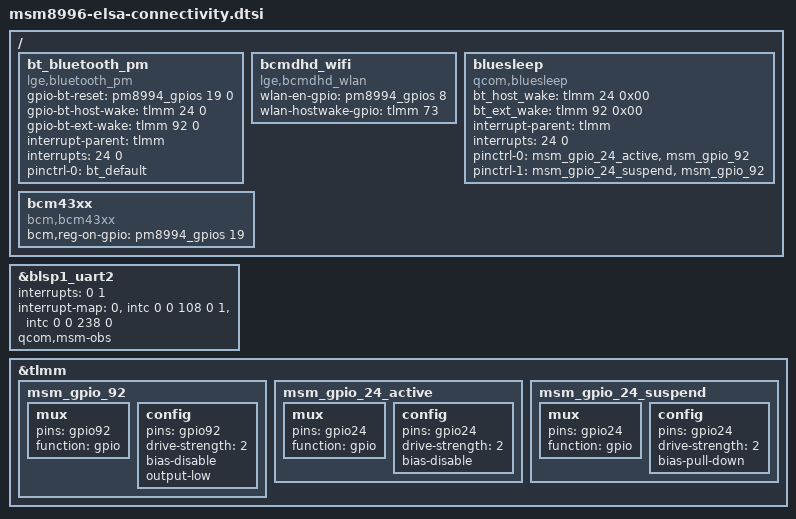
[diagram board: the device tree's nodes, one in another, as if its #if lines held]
/* Copyright (c) 2015, The Linux Foundation. All rights reserved.
 * Copyright (c) 2017, The LineageOS Project. All rights reserved.
 *
 * This program is free software; you can redistribute it and/or modify
 * it under the terms of the GNU General Public License version 2 and
 * only version 2 as published by the Free Software Foundation.
 *
 * This program is distributed in the hope that it will be useful,
 * but WITHOUT ANY WARRANTY; without even the implied warranty of
 * MERCHANTABILITY or FITNESS FOR A PARTICULAR PURPOSE.  See the
 * GNU General Public License for more details.
 */


#if (defined(CONFIG_LINE_DISCIPLINE_DRIVER) || defined(CONFIG_LINE_DISCIPLINE_DRIVER_MODULE)) && (defined(CONFIG_BT_BCM43XX) || defined(CONFIG_BT_BCM43XX_MODULE))
#error "CONFIG_LINE_DISCIPLINE_DRIVER and CONFIG_BT_BCM43XX conflict, cannot continue!"
#elif !defined(CONFIG_LINE_DISCIPLINE_DRIVER) && !defined(CONFIG_LINE_DISCIPLINE_DRIVER_MODULE) && !defined(CONFIG_BT_BCM43XX) && !defined(CONFIG_BT_BCM43XX_MODULE)
#warning "No Bluetooth implementation selected, are you aure about that?"
#endif


#if defined(CONFIG_LINE_DISCIPLINE_DRIVER) || defined(CONFIG_LINE_DISCIPLINE_DRIVER_MODULE)
/*[H1_BT_BRINGUP_S]*/
&blsp1_uart2 {
	interrupt-names = "core_irq", "bam_irq";
	interrupts = <0 1>;
	interrupt-map = <0 &intc 0 0 108 0
			1 &intc 0 0 238 0>;
	/delete-property/ qcom,inject-rx-on-wakeup;
	/delete-property/ qcom,rx-char-to-inject;
	qcom,msm-obs;
};
/*[H1_BT_BRINGUP_E]*/
#endif

/ {
#if defined(CONFIG_LINE_DISCIPLINE_DRIVER) || defined(CONFIG_LINE_DISCIPLINE_DRIVER_MODULE)
	/*[H1_BT_BRINGUP_S]*/
	bt_bluetooth_pm {
		compatible = "lge,bluetooth_pm";
		gpio-bt-reset = <&pm8994_gpios 19 0>;
		gpio-bt-host-wake = <&tlmm 24 0>;
		gpio-bt-ext-wake = <&tlmm 92 0>;
		interrupt-parent = <&tlmm>;
		interrupts = <24 0>;
		interrupt-names = "host_wake_interrupt";

		pinctrl-names = "bt_default";
		pinctrl-0 = <&bt_default>;
	};
	/*[H1_BT_BRINGUP_E]*/
#endif

	/* BCMDHD for Wi-Fi */
	bcmdhd_wifi {
		compatible = "lge,bcmdhd_wlan";
		wlan-en-gpio = <&pm8994_gpios 8 0>;
		wlan-hostwake-gpio = <&tlmm 73 0>;
	};

#if defined(CONFIG_BT_BCM43XX) || defined(CONFIG_BT_BCM43XX_MODULE)
	bluesleep {
		compatible = "qcom,bluesleep";
		bt_host_wake = <&tlmm 24 0x00>; /* BT_HOST_WAKE */
		bt_ext_wake = <&tlmm 92 0x00>; /* BT_DEV_WAKE */
		interrupt-parent = <&tlmm>;
		interrupts = <24 0>;
		interrupt-names = "host_wake";
		pinctrl-names = "default", "sleep";
		pinctrl-0 = <&msm_gpio_24_active &msm_gpio_92>;
		pinctrl-1 = <&msm_gpio_24_suspend &msm_gpio_92>;
	};

	bcm43xx {
		compatible = "bcm,bcm43xx";
		bcm,reg-on-gpio = <&pm8994_gpios 19 0x00>; /* BT_REG_ON */
	};
};

&tlmm {
	/* GPIO_92 : BT_DEV_WAKE */
	msm_gpio_92: msm_gpio_92 {
		mux {
			pins = "gpio92";
			function = "gpio";
		};

		config {
			pins = "gpio92";
			drive-strength = <2>;
			bias-disable;
			output-low;
		};
	};

	/* GPIO_24 : BT_HOST_WAKE */
	msm_gpio_24_active: msm_gpio_24_active {
		mux {
			pins = "gpio24";
			function = "gpio";
		};

		config {
			pins = "gpio24";
			drive-strength = <2>;
			bias-disable;
		};
	};
	msm_gpio_24_suspend: msm_gpio_24_suspend {
		mux {
			pins = "gpio24";
			function = "gpio";
		};

		config {
			pins = "gpio24";
			drive-strength = <2>;
			bias-pull-down;
		};
	};
#endif
};
